# STM32F100 register map
File version: 1.1
CPU: CM3 r1p1, little endian, no MPU, no FPU, 4 interrupt priority bits
Registers are 32-bit, read-write, reset 0x0 unless marked. A register's access mark holds for its fields unless they carry their own. Offsets are from the block's base; [hi:lo] are bit positions; {n}, {i} and the like mark numbered series.

## DBGMCU — Debug support
Base 0xE0042000
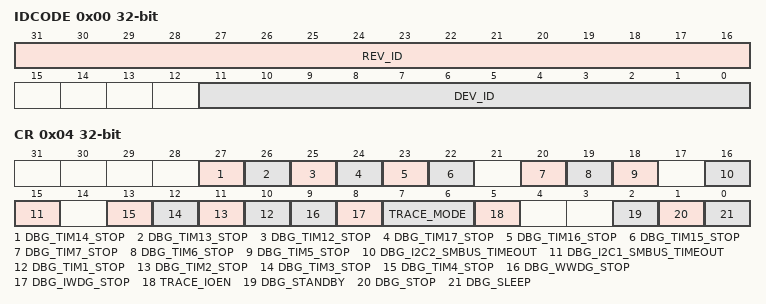
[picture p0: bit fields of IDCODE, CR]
0x00 IDCODE ro — DBGMCU_IDCODE
  [31:16] REV_ID, [11:0] DEV_ID
0x04 CR — DBGMCU_CR
  [27] DBG_TIM14_STOP, [26] DBG_TIM13_STOP, [25] DBG_TIM12_STOP, [24] DBG_TIM17_STOP, [23] DBG_TIM16_STOP, [22] DBG_TIM15_STOP, [20] DBG_TIM7_STOP, [19] DBG_TIM6_STOP, [18] DBG_TIM5_STOP, [16] DBG_I2C2_SMBUS_TIMEOUT, [15] DBG_I2C1_SMBUS_TIMEOUT, [n+9] DBG_TIM{n}_STOP (n=1..4), [9] DBG_WWDG_STOP, [8] DBG_IWDG_STOP, [7:6] TRACE_MODE, [5] TRACE_IOEN, [2] DBG_STANDBY, [1] DBG_STOP, [0] DBG_SLEEP

## CRC — CRC calculation unit
Base 0x40023000
0x00 DR reset 0xFFFFFFFF — Data register
  [31:0] DR — Data Register
0x04 IDR — Independent Data register
  [7:0] IDR
0x08 CR wo — Control register
  [0] RESET — Reset bit
    1=Resets the CRC calculation unit and sets the data register to 0xFFFF FFFF

## FLASH
Base 0x40022000
0x00 ACR — Flash access control register
  [3] HLFCYA — Flash half cycle access enable
0x04 KEYR wo — Flash key register
  [31:0] KEY — FPEC key
0x08 OPTKEYR wo — Flash option key register
  [31:0] OPTKEY — Option byte key
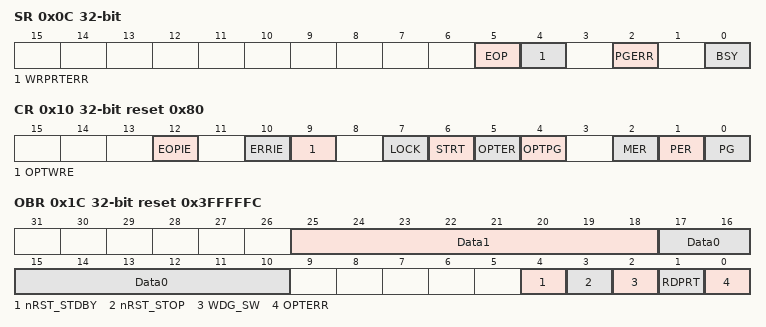
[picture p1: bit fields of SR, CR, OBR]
0x0C SR access per field — Status register
  [5] EOP rw — End of operation
  [4] WRPRTERR rw — Write protection error
  [2] PGERR rw — Programming error
  [0] BSY ro — Busy
0x10 CR reset 0x80 — Control register
  [12] EOPIE — End of operation interrupt enable
  [10] ERRIE — Error interrupt enable
  [9] OPTWRE — Option bytes write enable
  [7] LOCK
  [6] STRT — Start
  [5] OPTER — Option byte erase
  [4] OPTPG — Option byte programming
  [2] MER — Mass Erase
  [1] PER — Page Erase
  [0] PG — Programming
0x14 AR wo — Flash address register
  [31:0] FAR — Flash Address
0x1C OBR ro reset 0x3FFFFFC — Option byte register
  [25:18] Data1
  [17:10] Data0
  [4] nRST_STDBY
  [3] nRST_STOP
  [2] WDG_SW
  [1] RDPRT — Read protection
  [0] OPTERR — Option byte error
0x20 WRPR ro reset 0xFFFFFFFF — Write protection register
  [31:0] WRP — Write protect

## CEC — HDMI-CEC controller
Base 0x40007800
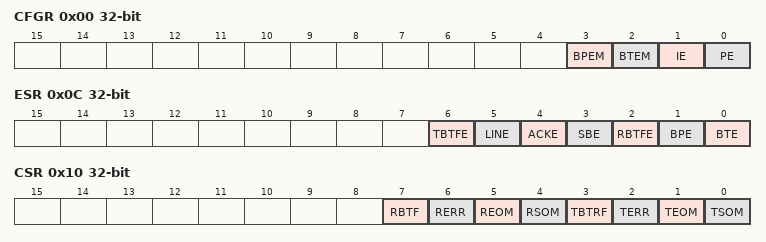
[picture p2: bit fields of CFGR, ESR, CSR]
0x00 CFGR — configuration register
  [3] BPEM — Bit period error mode
  [2] BTEM — Bit timing error mode
  [1] IE — Interrupt enable
  [0] PE — Peripheral enable
0x04 OAR — CEC own address register
  [3:0] OA — Own address
0x08 PRES — Rx Data Register
  [13:0] PRESC — CEC Rx Data Register
0x0C ESR ro — CEC error status register
  [6] TBTFE — Tx block transfer finished error
  [5] LINE — Line error
  [4] ACKE — Block acknowledge error
  [3] SBE — Start bit error
  [2] RBTFE — Rx block transfer finished error
  [1] BPE — Bit period error
  [0] BTE — Bit timing error
0x10 CSR — CEC control and status register
  [7] RBTF — Rx byte/block transfer finished
  [6] RERR — Rx error
  [5] REOM — Rx end of message
  [4] RSOM — Rx start of message
  [3] TBTRF — Tx byte transfer request or block transfer finished
  [2] TERR — Tx error
  [1] TEOM — Tx end of message
  [0] TSOM — Tx start of message
0x14 TXD — CEC Tx data register
  [7:0] TXD — Tx Data register
0x18 RXD ro — CEC Rx data register
  [7:0] RXD — Rx data

## NVIC — Nested Vectored Interrupt Controller
Base 0xE000E100
0x00 ISER0 — Interrupt Set-Enable Register
  [31:0] SETENA
0x04 ISER1 — Interrupt Set-Enable Register
  [31:0] SETENA
0x80 ICER0 — Interrupt Clear-Enable Register
  [31:0] CLRENA
0x84 ICER1 — Interrupt Clear-Enable Register
  [31:0] CLRENA
0x100 ISPR0 — Interrupt Set-Pending Register
  [31:0] SETPEND
0x104 ISPR1 — Interrupt Set-Pending Register
  [31:0] SETPEND
0x180 ICPR0 — Interrupt Clear-Pending Register
  [31:0] CLRPEND
0x184 ICPR1 — Interrupt Clear-Pending Register
  [31:0] CLRPEND
0x200 IABR0 ro — Interrupt Active Bit Register
  [31:0] ACTIVE
0x204 IABR1 ro — Interrupt Active Bit Register
  [31:0] ACTIVE
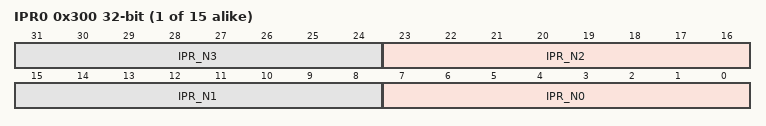
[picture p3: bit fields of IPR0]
{0x300+4i} IPR{i} (i=0..14) — Interrupt Priority Register
  [8n+7:8n] IPR_N{n} (n=0..3)

## MPU — Memory protection unit
Base 0xE000ED90
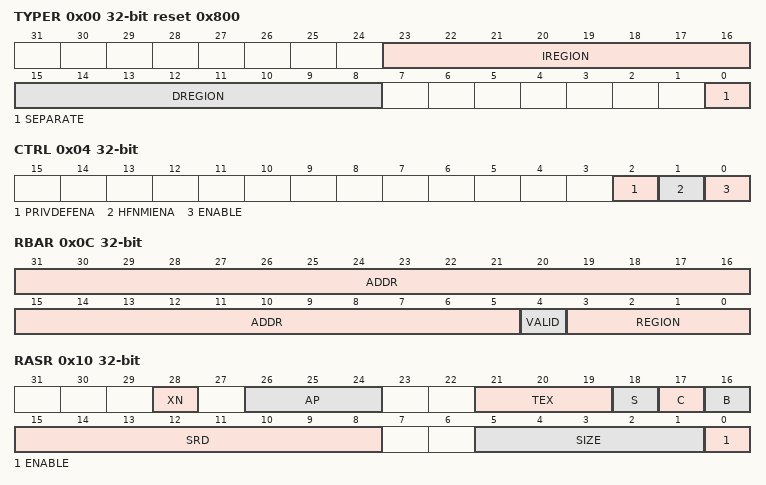
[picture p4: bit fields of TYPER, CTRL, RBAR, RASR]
0x00 TYPER ro reset 0x800 — MPU type register
  [23:16] IREGION — Number of MPU instruction regions
  [15:8] DREGION — Number of MPU data regions
  [0] SEPARATE — Separate flag
0x04 CTRL ro — MPU control register
  [2] PRIVDEFENA — Enable priviliged software access to default memory map
  [1] HFNMIENA — Enables the operation of MPU during hard fault
  [0] ENABLE — Enables the MPU
0x08 RNR — MPU region number register
  [7:0] REGION — MPU region
0x0C RBAR — MPU region base address register
  [31:5] ADDR — Region base address field
  [4] VALID — MPU region number valid
  [3:0] REGION — MPU region field
0x10 RASR — MPU region attribute and size register
  [28] XN — Instruction access disable bit
  [26:24] AP — Access permission
  [21:19] TEX — memory attribute
  [18] S — Shareable memory attribute
  [17] C — memory attribute
  [16] B — memory attribute
  [15:8] SRD — Subregion disable bits
  [5:1] SIZE — Size of the MPU protection region
  [0] ENABLE — Region enable bit.

## SCB_ACTRL — System control block ACTLR
Base 0xE000E008
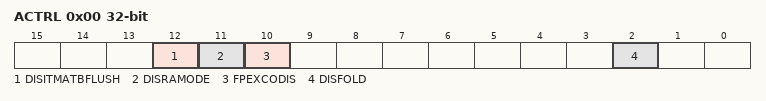
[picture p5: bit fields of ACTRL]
0x00 ACTRL — Auxiliary control register
  [12] DISITMATBFLUSH, [11] DISRAMODE, [10] FPEXCODIS, [2] DISFOLD

## NVIC_STIR — Nested vectored interrupt controller
Base 0xE000EF00
0x00 STIR — Software trigger interrupt register
  [8:0] INTID — Software generated interrupt ID

## STK — SysTick timer
Base 0xE000E010
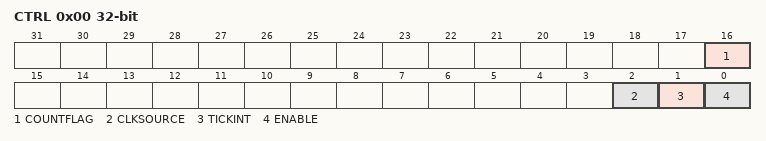
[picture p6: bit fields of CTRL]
0x00 CTRL — SysTick control and status register
  [16] COUNTFLAG
  [2] CLKSOURCE — Clock source selection
  [1] TICKINT — SysTick exception request enable
  [0] ENABLE — Counter enable
0x04 LOAD_ — SysTick reload value register
  [23:0] RELOAD — RELOAD value
0x08 VAL — SysTick current value register
  [23:0] CURRENT — Current counter value
0x0C CALIB — SysTick calibration value register
  [23:0] TENMS — Calibration value
